# RFCORE_XREG_CM register map
Vendor: Texas Instruments
Peripheral module from a debugger description file (folder cc2538).
Registers are 32-bit, access per field, no defined reset value unless marked. A register's access mark holds for its fields unless they carry their own. Offsets are as the file gives them; lines under a group give offsets from that group; [hi:lo] are bit positions; {n}, {i} and the like mark numbered series; 'fields as' and 'values as' point back to an identical list; <NAME> marks a mode.

## RFCORE_XREG — Register fields should be considered static unless otherwise noted as dynamic.
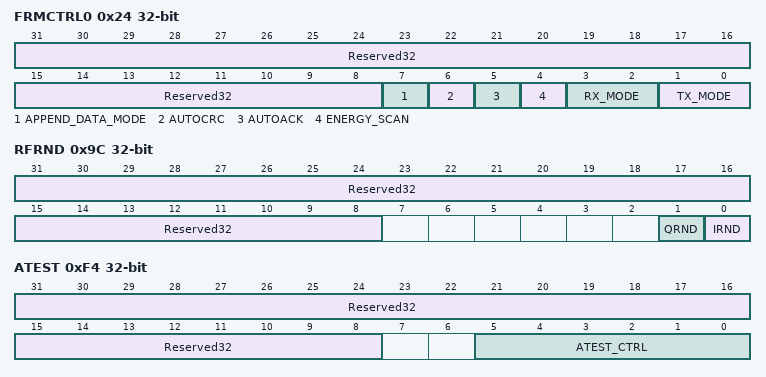
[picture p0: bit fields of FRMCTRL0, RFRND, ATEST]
0x24 FRMCTRL0 — Frame handling
  [31:8] Reserved32 ro — This register is 8 bits in a 32-bit address space.
  [7] APPEND_DATA_MODE rw — When AUTOCRC = 0: Don't care When AUTOCRC = 1: 0: RSSI + The CRC_OK bit and the 7-bit correlation value are appended at the end of each received frame 1: RSSI + The CRC_OK bit and the 7-bit SRCRESINDEX are appended at the end of each received frame.
  [6] AUTOCRC rw — In TX 1: A CRC-16 (ITU-T) is generated in hardware and appended to the transmitted frame. There is no need to write the last 2 bytes to TXBUF. 0: No CRC-16 is appended to the frame. The last 2 bytes of the frame must be generated manually and written to TXBUF (if not, TX_UNDERFLOW occurs). In RX 1: The CRC-16 is checked in hardware, and replaced in the RXFIFO by a 16-bit status word which contains a CRC OK bit. The status word is controllable through APPEND_DATA_MODE. 0: The last 2 bytes of the frame (CRC-16 field) are stored in the RX FIFO. The CRC (if any) must be done manually. This setting does not influence acknowledgment transmission (including AUTOACK).
  [5] AUTOACK rw — Defines whether the radio automatically transmits acknowledge frames or not. When autoack is enabled, all frames that are accepted by address filtering, have the acknowledge request flag set, and have a valid CRC are automatically acknowledged 12 symbol periods after being received. 0: Autoack disabled 1: Autoack enabled
  [4] ENERGY_SCAN rw — Defines whether the RSSI register contains the most-recent signal strength or the peak signal strength since the energy scan was enabled. 0: Most-recent signal strength 1: Peak signal strength
  [3:2] RX_MODE rw — Set RX modes. 00: Normal operation, use RX FIFO 01: Receive serial mode, output received data on to IOC; infinite RX 10: RX FIFO looping ignore overflow in RX FIFO; infinite reception 11: Same as normal operation except that symbol search is disabled. Can be used for RSSI or CCA measurements when finding symbol is not desired.
  [1:0] TX_MODE rw — Set test modes for TX. 00: Normal operation, transmit TX FIFO 01: Reserved, should not be used 10: TX FIFO looping ignore underflow in TX FIFO and read cyclic; infinite transmission 11: Send random data from CRC; infinite transmission
0x9C RFRND ro — Random data
  [31:8] Reserved32 — This register is 8 bits in a 32-bit address space.
  [1] QRND — Random bit from the Q channel of the receiver
  [0] IRND — Random bit from the I channel of the receiver
0xF4 ATEST — Analog test control
  [31:8] Reserved32 rw — This register is 8 bits in a 32-bit address space.
  [5:0] ATEST_CTRL rw — Controls the analog test mode: 00 0000: Disabled 00 0001: Enables the temperature sensor (see also the CCTEST_TR0 register description). Other values reserved.
